# LPC824 register map
Vendor: nxp.com; File version: 1.0
CPU: CM0PLUS r0p0, little endian, no MPU, no FPU, VTOR, 2 interrupt priority bits
Registers are 32-bit, read-write, reset 0x0 unless marked. A register's access mark holds for its fields unless they carry their own. Offsets are from the block's base; [hi:lo] are bit positions; {n}, {i} and the like mark numbered series.

## INPUTMUX — LPC82x Input multiplexing (INPUT MUX)
Base 0x40028000
{0x0+4i} DMA_ITRIG_INMUX[{i}] (i=0..17) reset 0xF — Trigger select register for DMA channel
  [3:0] INP — Input mux register for trigger inputs 0 to 23 connected to DMA channel 0. Selects from ADC, SCT, ACMP, pin interrupts, and DMA requests.
    0=ADC_SEQA_IRQ; 1=ADC_SEQB_IRQ; 2=SCT_DMA0; 3=SCT_DMA1; 4=ACMP_O; 5=PININT0; 6=PININT1; 7=DMA_INMUX_INMUX0 (DMA trigger mux 0); 8=DMA_INMUX_INMUX1 (DMA trigger mux 1); 9=None
{0x4000+4i} DMA_INMUX_INMUX[{i}] (i=0..1) reset 0x1F — DMA output trigger selection to become DMA trigger 7 and DMA trigger 8
  [4:0] INP — DMA trigger output number (decimal value) for DMA channel n (n = 0 to 17).
{0x4020+4i} SCT0_INMUX[{i}] (i=0..3) reset 0xF — input select register for SCT
  [3:0] INP_N — Input mux register for SCT input n (n = 0 to 3). 0 = sct input 0 1=sct input 1 2= sct input 2 3= sct input 3 4= adc_thcmp_irq 5 = comparator out 6=arm_txev 7=debug_halted
    {v}=SCT_PIN{v-1} (v=1..4); 5=ADC_THCMP_IRQ; 6=ACMP_O; 7=ARM_TXEV; 8=DEBUG_HALTED; 9=None; 10=None

## FLASH_CTRL — LPC82x NVMC flash controller
Base 0x40040000
0x10 FLASHCFG reset 0x1 — Flash configuration register
  [1:0] FLASHTIM — Flash memory access time. FLASHTIM +1 is equal to the number of system clocks used for flash access.
    0=ONE_SYSTEM_CLOCK_FLASH_ACCESS (1 system clock flash access time.); 1=TWO_SYSTEM_CLOCK_FLASH_ACCESS (2 system clock flash access time.)
0x20 FMSSTART — Flash signature start address register
  [16:0] START — Signature generation start address (corresponds to AHB byte address bits[18:2]).
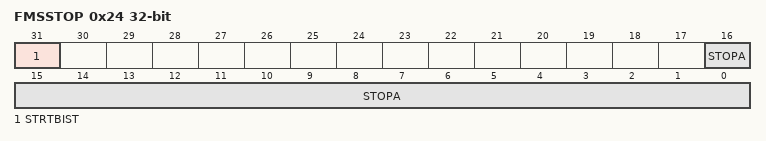
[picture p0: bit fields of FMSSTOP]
0x24 FMSSTOP — Flash signaure stop address register
  [31] STRTBIST — When this bit is written to 1, signature generation starts. At the end of signature generation, this bit is automatically cleared.
  [16:0] STOPA — Stop address for signature generation (the word specified by STOP is included in the address range). The address is in units of memory words, not bytes.
0x2C FMSW0 ro reset not defined — Flash signature generation result register returns the flash signature produced by the embedded signature generator..
  [31:0] SIG — 32-bit signature.
0xFE0 FMSTAT ro — Flash signature generation status bit
  [1] SIGNATURE_DONE — This status bit is set at the end of signature computation
0xFE8 FMSTATCLR wo — Clear FLASH signature generation status bit
  [1] SIGNATURE_DONE_CLR — When the bit is written to 1, the SIGNATURE_DONE bit is cleared.

## CRC — LPC5411x CRC engine
Base 0x50000000
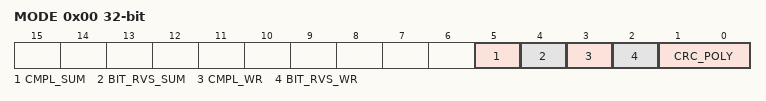
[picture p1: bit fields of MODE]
0x00 MODE — CRC mode register
  [5] CMPL_SUM — CRC sum complement: 1 = 1's complement for CRC_SUM 0 = No 1's complement for CRC_SUM
  [4] BIT_RVS_SUM — CRC sum bit order: 1 = Bit order reverse for CRC_SUM 0 = No bit order reverse for CRC_SUM
  [3] CMPL_WR — Data complement: 1 = 1's complement for CRC_WR_DATA 0 = No 1's complement for CRC_WR_DATA
  [2] BIT_RVS_WR — Data bit order: 1 = Bit order reverse for CRC_WR_DATA (per byte) 0 = No bit order reverse for CRC_WR_DATA (per byte)
  [1:0] CRC_POLY — CRC polynomial: 1X = CRC-32 polynomial 01 = CRC-16 polynomial 00 = CRC-CCITT polynomial
0x04 SEED reset 0xFFFF — CRC seed register
  [31:0] CRC_SEED — A write access to this register will load CRC seed value to CRC_SUM register with selected bit order and 1's complement pre-processes. A write access to this register will overrule the CRC calculation in progresses.
0x08 SUM ro reset 0xFFFF (SUM_WR_DATA view) — CRC checksum register
  [31:0] CRC_SUM — The most recent CRC sum can be read through this register with selected bit order and 1's complement post-processes.
0x08 WR_DATA wo reset not defined (SUM_WR_DATA view) — CRC data register
  [31:0] CRC_WR_DATA — Data written to this register will be taken to perform CRC calculation with selected bit order and 1's complement pre-process. Any write size 8, 16 or 32-bit are allowed and accept back-to-back transactions.

## Notices in the file
Copyright 2016-2019 NXP
All rights reserved.
SPDX-License-Identifier: BSD-3-Clause
